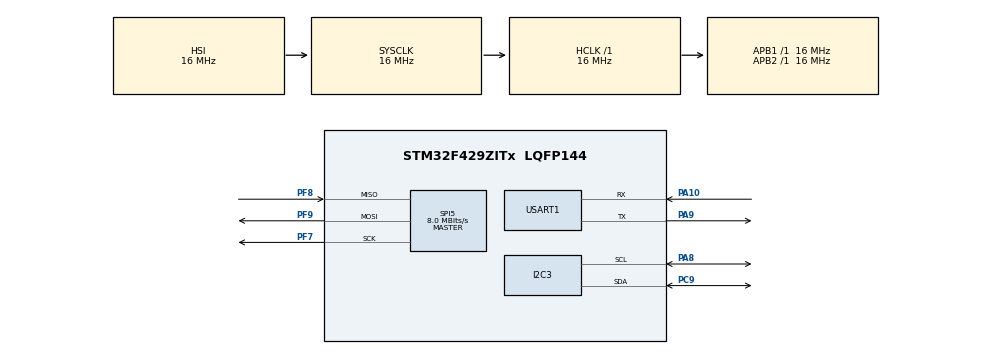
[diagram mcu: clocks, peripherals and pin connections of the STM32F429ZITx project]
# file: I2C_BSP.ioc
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Mcu.Family=STM32F4
Mcu.Name=STM32F429ZITx
Mcu.Package=LQFP144
NVIC.PriorityGroup=NVIC_PRIORITYGROUP_4
PA10.Mode=Asynchronous
PA10.Signal=USART1_RX
PA8.Mode=I2C
PA8.Signal=I2C3_SCL
PA9.Mode=Asynchronous
PA9.Signal=USART1_TX
PC9.Mode=I2C
PC9.Signal=I2C3_SDA
PF7.Mode=Full_Duplex_Master
PF7.Signal=SPI5_SCK
PF8.Mode=Full_Duplex_Master
PF8.Signal=SPI5_MISO
PF9.Mode=Full_Duplex_Master
PF9.Signal=SPI5_MOSI
ProjectManager.HeapSize=0x200
ProjectManager.StackSize=0x400
ProjectManager.TargetToolchain=TrueSTUDIO
RCC.AHBFreq_Value=16000000
RCC.APB1Freq_Value=16000000
RCC.APB2Freq_Value=16000000
RCC.CortexFreq_Value=16000000
RCC.HSE_VALUE=25000000
RCC.HSI_VALUE=16000000
RCC.LSE_VALUE=32768
RCC.SYSCLKFreq_VALUE=16000000
RCC.VCOOutputFreq_Value=192000000
SPI5.CalculateBaudRate=8.0 MBits/s
SPI5.Direction=SPI_DIRECTION_2LINES
SPI5.Mode=SPI_MODE_MASTER
SPI5.VirtualType=VM_MASTER
USART1.VirtualMode=VM_ASYNC
board=custom

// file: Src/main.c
/* USER CODE BEGIN Header */
/**
  ******************************************************************************
  * @file           : main.c
  * @brief          : Main program body
  ******************************************************************************
  * @attention
  *
  * <h2><center>&copy; Copyright (c) 2019 STMicroelectronics.
  * All rights reserved.</center></h2>
  *
  * This software component is licensed by ST under BSD 3-Clause license,
  * the "License"; You may not use this file except in compliance with the
  * License. You may obtain a copy of the License at:
  *                        opensource.org/licenses/BSD-3-Clause
  *
  ******************************************************************************
  */
/* USER CODE END Header */

#include "main.h"
#include "stm32f429i_discovery.h"
#include "stm32f429i_discovery_ts.h"
#include <stdio.h>

I2C_HandleTypeDef hi2c3;

SPI_HandleTypeDef hspi5;

UART_HandleTypeDef huart1;

void SystemClock_Config(void);
static void MX_GPIO_Init(void);
static void MX_USART1_UART_Init(void);
static void MX_I2C3_Init(void);
static void MX_SPI5_Init(void);

/* USER CODE BEGIN 0 */
int _write(int file, char *ptr, int len)
{
	HAL_UART_Transmit(&huart1, (uint8_t *)ptr, len, 0xFFFFFFFF);
	return len;
}
/* USER CODE END 0 */

int main(void)
{

  /* MCU Configuration--------------------------------------------------------*/

  /* Reset of all peripherals, Initializes the Flash interface and the Systick. */
  HAL_Init();

  /* Configure the system clock */
  SystemClock_Config();

  /* Initialize all configured peripherals */
  MX_GPIO_Init();
  MX_USART1_UART_Init();
  MX_I2C3_Init();
  MX_SPI5_Init();
  /* USER CODE BEGIN 2 */

  TS_StateTypeDef stTouch;
  BSP_TS_Init(240, 320);
  /* USER CODE END 2 */

  /* Infinite loop */
  while (1)
  {

    /* USER CODE BEGIN 3 */
	  BSP_TS_GetState(&stTouch);
	  if(stTouch.TouchDetected) {
		  printf("X : %d\r\n", stTouch.X);
		  printf("Y : %d\r\n", stTouch.Y);
		  printf("Z : %d\r\n", stTouch.Z);
	  }
  }
  /* USER CODE END 3 */
}

void SystemClock_Config(void)
{
  RCC_OscInitTypeDef RCC_OscInitStruct = {0};
  RCC_ClkInitTypeDef RCC_ClkInitStruct = {0};

  /** Configure the main internal regulator output voltage
  */
  __HAL_RCC_PWR_CLK_ENABLE();
  __HAL_PWR_VOLTAGESCALING_CONFIG(PWR_REGULATOR_VOLTAGE_SCALE3);
  /** Initializes the CPU, AHB and APB busses clocks
  */
  RCC_OscInitStruct.OscillatorType = RCC_OSCILLATORTYPE_HSI;
  RCC_OscInitStruct.HSIState = RCC_HSI_ON;
  RCC_OscInitStruct.HSICalibrationValue = RCC_HSICALIBRATION_DEFAULT;
  RCC_OscInitStruct.PLL.PLLState = RCC_PLL_NONE;
  if (HAL_RCC_OscConfig(&RCC_OscInitStruct) != HAL_OK)
  {
    Error_Handler();
  }
  /** Initializes the CPU, AHB and APB busses clocks
  */
  RCC_ClkInitStruct.ClockType = RCC_CLOCKTYPE_HCLK|RCC_CLOCKTYPE_SYSCLK
                              |RCC_CLOCKTYPE_PCLK1|RCC_CLOCKTYPE_PCLK2;
  RCC_ClkInitStruct.SYSCLKSource = RCC_SYSCLKSOURCE_HSI;
  RCC_ClkInitStruct.AHBCLKDivider = RCC_SYSCLK_DIV1;
  RCC_ClkInitStruct.APB1CLKDivider = RCC_HCLK_DIV1;
  RCC_ClkInitStruct.APB2CLKDivider = RCC_HCLK_DIV1;

  if (HAL_RCC_ClockConfig(&RCC_ClkInitStruct, FLASH_LATENCY_0) != HAL_OK)
  {
    Error_Handler();
  }
}

static void MX_I2C3_Init(void)
{

  hi2c3.Instance = I2C3;
  hi2c3.Init.ClockSpeed = 100000;
  hi2c3.Init.DutyCycle = I2C_DUTYCYCLE_2;
  hi2c3.Init.OwnAddress1 = 0;
  hi2c3.Init.AddressingMode = I2C_ADDRESSINGMODE_7BIT;
  hi2c3.Init.DualAddressMode = I2C_DUALADDRESS_DISABLE;
  hi2c3.Init.OwnAddress2 = 0;
  hi2c3.Init.GeneralCallMode = I2C_GENERALCALL_DISABLE;
  hi2c3.Init.NoStretchMode = I2C_NOSTRETCH_DISABLE;
  if (HAL_I2C_Init(&hi2c3) != HAL_OK)
  {
    Error_Handler();
  }
  /** Configure Analogue filter
  */
  if (HAL_I2CEx_ConfigAnalogFilter(&hi2c3, I2C_ANALOGFILTER_ENABLE) != HAL_OK)
  {
    Error_Handler();
  }
  /** Configure Digital filter
  */
  if (HAL_I2CEx_ConfigDigitalFilter(&hi2c3, 0) != HAL_OK)
  {
    Error_Handler();
  }

}

static void MX_SPI5_Init(void)
{

  /* SPI5 parameter configuration*/
  hspi5.Instance = SPI5;
  hspi5.Init.Mode = SPI_MODE_MASTER;
  hspi5.Init.Direction = SPI_DIRECTION_2LINES;
  hspi5.Init.DataSize = SPI_DATASIZE_8BIT;
  hspi5.Init.CLKPolarity = SPI_POLARITY_LOW;
  hspi5.Init.CLKPhase = SPI_PHASE_1EDGE;
  hspi5.Init.NSS = SPI_NSS_SOFT;
  hspi5.Init.BaudRatePrescaler = SPI_BAUDRATEPRESCALER_2;
  hspi5.Init.FirstBit = SPI_FIRSTBIT_MSB;
  hspi5.Init.TIMode = SPI_TIMODE_DISABLE;
  hspi5.Init.CRCCalculation = SPI_CRCCALCULATION_DISABLE;
  hspi5.Init.CRCPolynomial = 10;
  if (HAL_SPI_Init(&hspi5) != HAL_OK)
  {
    Error_Handler();
  }

}

static void MX_USART1_UART_Init(void)
{

  huart1.Instance = USART1;
  huart1.Init.BaudRate = 115200;
  huart1.Init.WordLength = UART_WORDLENGTH_8B;
  huart1.Init.StopBits = UART_STOPBITS_1;
  huart1.Init.Parity = UART_PARITY_NONE;
  huart1.Init.Mode = UART_MODE_TX_RX;
  huart1.Init.HwFlowCtl = UART_HWCONTROL_NONE;
  huart1.Init.OverSampling = UART_OVERSAMPLING_16;
  if (HAL_UART_Init(&huart1) != HAL_OK)
  {
    Error_Handler();
  }

}

static void MX_GPIO_Init(void)
{

  /* GPIO Ports Clock Enable */
  __HAL_RCC_GPIOF_CLK_ENABLE();
  __HAL_RCC_GPIOC_CLK_ENABLE();
  __HAL_RCC_GPIOA_CLK_ENABLE();

}

void Error_Handler(void)
{
}

/************************ (C) COPYRIGHT STMicroelectronics *****END OF FILE****/
